# CC13x0 register map
File version: 2.0
CPU: CM3 r2p1, little endian, no MPU, no FPU, 0x3 interrupt priority bits, 0x0 interrupts
Registers are 32-bit, read-write, reset 0x0 unless marked. A register's access mark holds for its fields unless they carry their own. Offsets are from the block's base; [hi:lo] are bit positions; {n}, {i} and the like mark numbered series.

## AON_RTC — This component control the Real Time Clock residing in AON Note: This module is only supporting 32 bit ReadWrite access.
Base 0x40092000
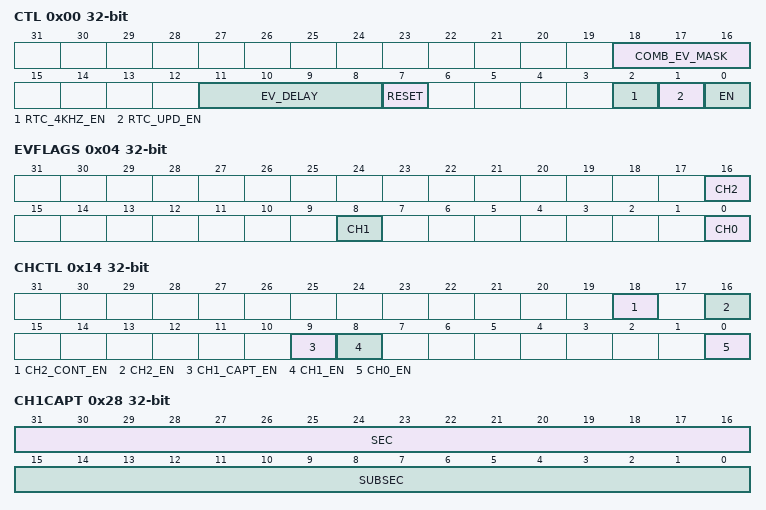
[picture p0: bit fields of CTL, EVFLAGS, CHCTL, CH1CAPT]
0x00 CTL — Control This register contains various bitfields for configuration of RTC
  [18:16] COMB_EV_MASK, [11:8] EV_DELAY, [7] RESET write-1-clears, [2] RTC_4KHZ_EN, [1] RTC_UPD_EN, [0] EN
0x04 EVFLAGS — Event Flags, RTC Status This register contains event flags from the 3 RTC channels. Each flag will be cleared when writing a '1' to the corresponding bitfield.
  [16] CH2 write-1-clears, [8] CH1 write-1-clears, [0] CH0 write-1-clears
0x08 SEC — Second Counter Value, Integer Part
  [31:0] VALUE
0x0C SUBSEC — Second Counter Value, Fractional Part
  [31:0] VALUE
0x10 SUBSECINC ro reset 0x800000 — Subseconds Increment Value added to SUBSEC.VALUE on every SCLK_LFclock cycle.
  [23:0] VALUEINC
0x14 CHCTL — Channel Configuration
  [18] CH2_CONT_EN, [16] CH2_EN, [9] CH1_CAPT_EN, [8] CH1_EN, [0] CH0_EN
{0x18+4i} CH{i}CMP (i=0..2) — Channel {i} Compare Value
  [31:0] VALUE
0x24 CH2CMPINC — Channel 2 Compare Value Auto-increment This register is primarily used to generate periodical wake-up for the AUX_SCE module, through the [AUX_EVCTL.EVSTAT0.AON_RTC] event.
  [31:0] VALUE
0x28 CH1CAPT ro — Channel 1 Capture Value If CHCTL.CH1_EN = 1and CHCTL.CH1_CAPT_EN = 1, capture occurs on each rising edge of the event selected in AON_EVENT:RTCSEL.
  [31:16] SEC, [15:0] SUBSEC
0x2C SYNC — AON Synchronization This register is used for synchronizing between MCU and entire AON domain.
  [0] WBUSY

## AON_SYSCTL — This component controls AON_SYSCTL, which is the device's system controller. Note: This module is only supporting 32 bit ReadWrite access from MCU
Base 0x40090000
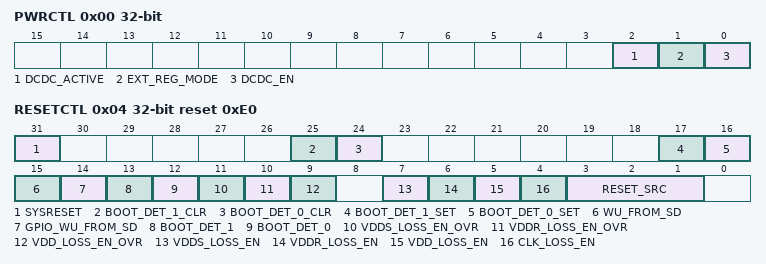
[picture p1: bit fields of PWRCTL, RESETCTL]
0x00 PWRCTL — Power Management This register controls bitfields for setting low level power management features such as selection of regulator for VDDR supply and control of IO ring where certain segments can be enabled / disabled.
  [2] DCDC_ACTIVE, [1] EXT_REG_MODE, [0] DCDC_EN
0x04 RESETCTL reset 0xE0 — Reset Management This register contains bitfields releated to system reset such as reset source and reset request and control of brown out resets.
  [31] SYSRESET, [25] BOOT_DET_1_CLR, [24] BOOT_DET_0_CLR, [17] BOOT_DET_1_SET, [16] BOOT_DET_0_SET, [15] WU_FROM_SD, [14] GPIO_WU_FROM_SD, [13] BOOT_DET_1, [12] BOOT_DET_0, [11] VDDS_LOSS_EN_OVR, [10] VDDR_LOSS_EN_OVR, [9] VDD_LOSS_EN_OVR, [7] VDDS_LOSS_EN, [6] VDDR_LOSS_EN, [5] VDD_LOSS_EN, [4] CLK_LOSS_EN, [3:1] RESET_SRC
0x08 SLEEPCTL — Sleep Mode This register is used to unfreeze the IO pad ring after waking up from SHUTDOWN
  [0] IO_PAD_SLEEP_DIS

## AON_WUC — This component control the Wakeup controller residing in the AON domain. Note: This module is only supporting 32 bit ReadWrite access from MCU
Base 0x40091000
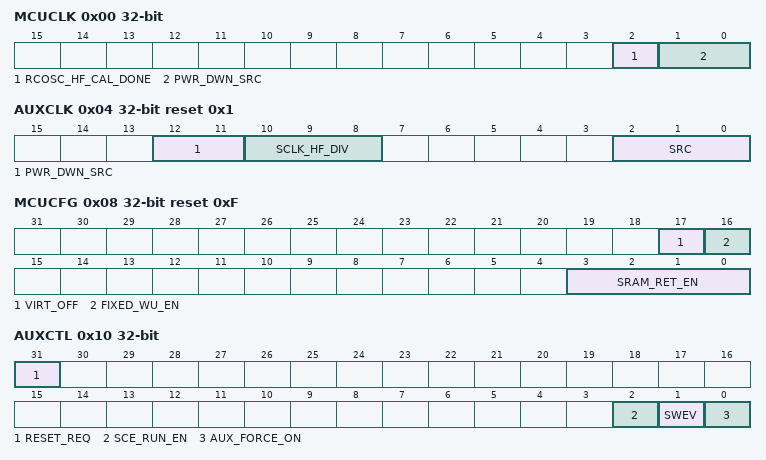
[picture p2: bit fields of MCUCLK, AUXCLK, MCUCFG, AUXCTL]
0x00 MCUCLK — MCU Clock Management This register contains bitfields related to the MCU clock.
  [2] RCOSC_HF_CAL_DONE, [1:0] PWR_DWN_SRC
0x04 AUXCLK reset 0x1 — AUX Clock Management This register contains bitfields that are relevant for setting up the clock to the AUX domain.
  [12:11] PWR_DWN_SRC, [10:8] SCLK_HF_DIV, [2:0] SRC
0x08 MCUCFG reset 0xF — MCU Configuration This register contains power management related bitfields for the MCU domain.
  [17] VIRT_OFF, [16] FIXED_WU_EN, [3:0] SRAM_RET_EN
0x0C AUXCFG reset 0x1 — AUX Configuration This register contains power management related signals for the AUX domain.
  [0] RAM_RET_EN
0x10 AUXCTL — AUX Control This register contains events and control signals for the AUX domain.
  [31] RESET_REQ, [2] SCE_RUN_EN, [1] SWEV, [0] AUX_FORCE_ON
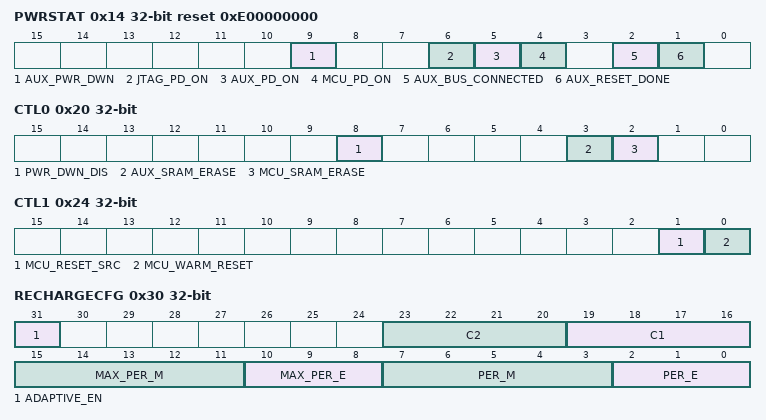
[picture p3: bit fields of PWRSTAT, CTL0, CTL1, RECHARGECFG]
0x14 PWRSTAT reset 0xE00000000 — Power Status This register is used to monitor various power management related signals in AON. Most signals are for test, calibration and debug purpose only, and others can be used to detect that AUX or JTAG domains are powered up.
  [9] AUX_PWR_DWN, [6] JTAG_PD_ON, [5] AUX_PD_ON, [4] MCU_PD_ON, [2] AUX_BUS_CONNECTED, [1] AUX_RESET_DONE
0x18 SHUTDOWN — Shutdown Control This register contains bitfields required for entering shutdown mode
  [0] EN
0x20 CTL0 — Control 0 This register contains various chip level control and debug bitfields.
  [8] PWR_DWN_DIS, [3] AUX_SRAM_ERASE, [2] MCU_SRAM_ERASE
0x24 CTL1 — Control 1 This register contains various chip level control and debug bitfields.
  [1] MCU_RESET_SRC write-1-clears, [0] MCU_WARM_RESET write-1-clears
0x30 RECHARGECFG — Recharge Controller Configuration This register sets all relevant patameters for controlling the recharge algorithm.
  [31] ADAPTIVE_EN, [23:20] C2, [19:16] C1, [15:11] MAX_PER_M, [10:8] MAX_PER_E, [7:3] PER_M, [2:0] PER_E
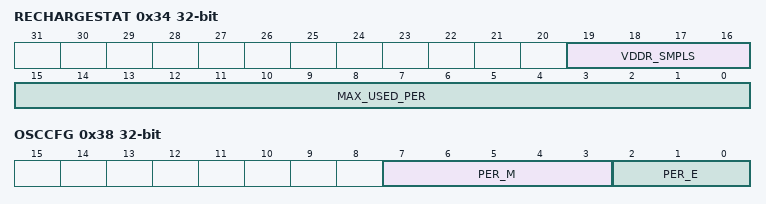
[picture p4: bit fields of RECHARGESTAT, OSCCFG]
0x34 RECHARGESTAT — Recharge Controller Status This register controls various status registers which are updated during recharge. The register is mostly intended for test and debug.
  [19:16] VDDR_SMPLS, [15:0] MAX_USED_PER
0x38 OSCCFG — Oscillator Configuration This register sets the period for Amplitude compensation requests sent to the oscillator control system. The amplitude compensations is only applicable when XOSC_HF is running in low power mode.
  [7:3] PER_M, [2:0] PER_E
0x40 JTAGCFG reset 0x100 — JTAG Configuration This register contains control for configuration of the JTAG domain,- hereunder access permissions for each TAP.
  [8] JTAG_PD_FORCE_ON
0x44 JTAGUSERCODE reset 0xB99A02F — JTAG USERCODE Boot code copies the JTAG USERCODE to this register from where it is forwarded to the debug subsystem.
  [31:0] USER_CODE
